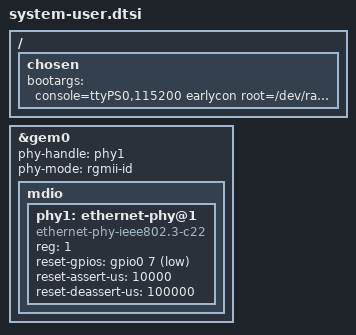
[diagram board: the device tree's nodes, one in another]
/include/ "system-conf.dtsi"
/ {
	chosen {
		bootargs = "console=ttyPS0,115200 earlycon root=/dev/ram0 rw net.ifnames=0";
	};
};

&gem0 {
	phy-handle = <&phy1>;
	phy-mode = "rgmii-id";

	mdio {
		#address-cells = <1>;
		#size-cells = <0>;

		phy1: ethernet-phy@1 {
			compatible = "ethernet-phy-ieee802.3-c22";
			reg = <1>;
			/* MIO7 PHY reset is active low; 1 = GPIO_ACTIVE_LOW. */
			reset-gpios = <&gpio0 7 1>;
			reset-assert-us = <10000>;
			reset-deassert-us = <100000>;
		};
	};
};
